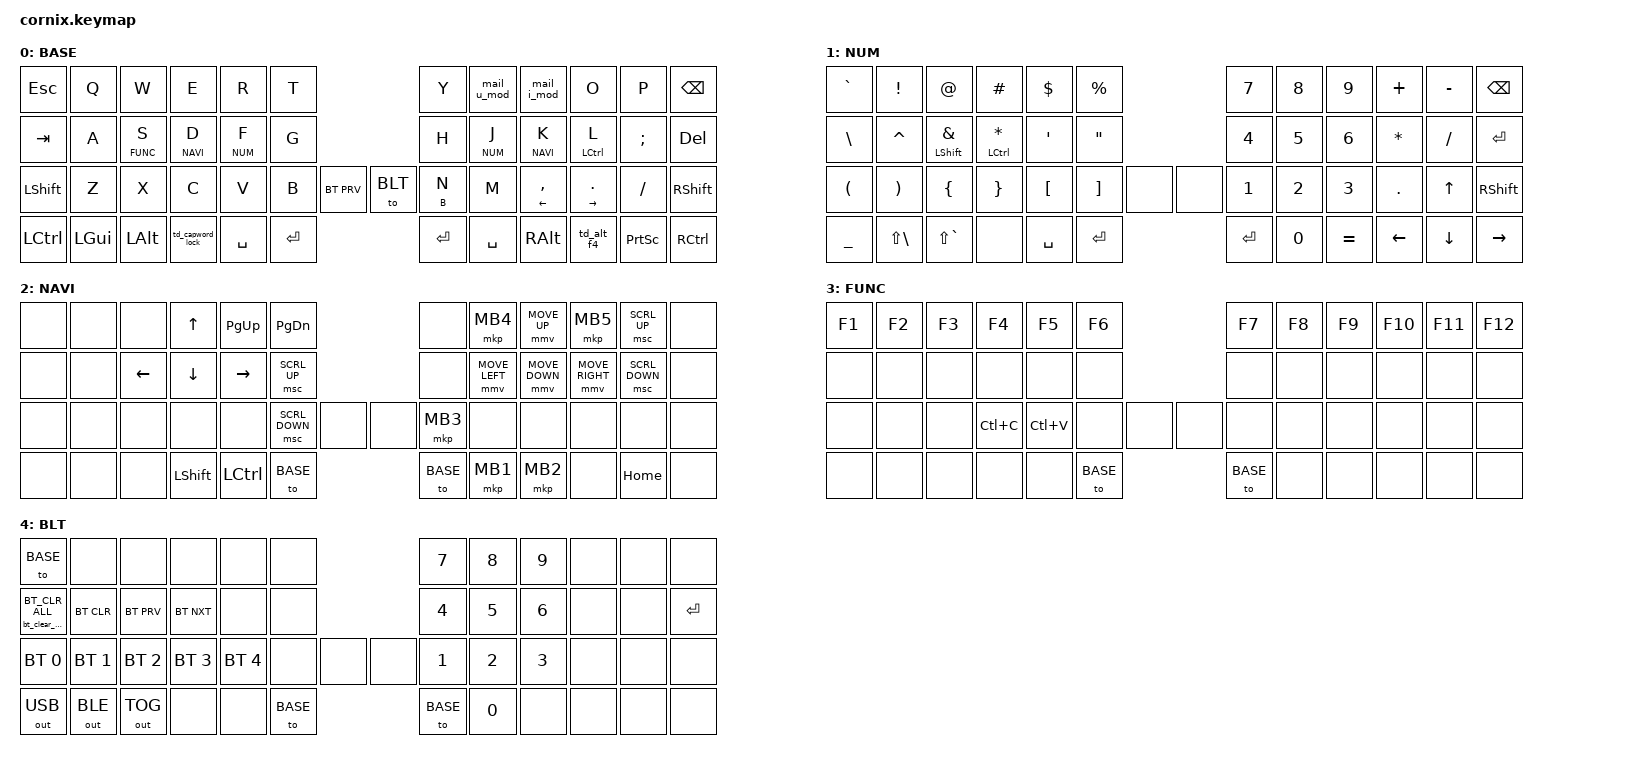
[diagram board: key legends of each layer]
/*
 * Copyright (c) 2020 The ZMK Contributors
 *
 * SPDX-License-Identifier: MIT
 */

#include "zmk-helpers/helper.h"
#include "includes/cornix54.h"

// Layer Mapping

#define BASE 0
#define NUM  1
#define NAVI 2
#define FUNC 3
#define BLT  4

// Group key positions in header files

#define KEYS_L LT0 LT1 LT2 LT3 LT4 LT5 LM0 LM1 LM2 LM3 LM4 LM5 LB0 LB1 LB2 LB3 LB4 LB5
#define KEYS_R RT0 RT1 RT2 RT3 RT4 RT5 RM0 RM1 RM2 RM3 RM4 RM5 RB0 RB1 RB2 RB3 RB4 RB5
#define KEYS_T LH1 LH0 RH0 RH1
#define ZMK_POINTING_DEFAULT_SCRL_VAL 15
#define ZMK_POINTING_DEFAULT_MOVE_VAL 1800

#include <behaviors.dtsi>
#include <dt-bindings/zmk/bt.h>
#include <dt-bindings/zmk/keys.h>
#include <dt-bindings/zmk/modifiers.h>
#include <dt-bindings/zmk/outputs.h>
#include <dt-bindings/zmk/pointing.h>

/ {
    behaviors {
        hm_l: homerow_mods_left {
            compatible = "zmk,behavior-hold-tap";
            #binding-cells = <2>;
            bindings = <&kp>, <&kp>;

            flavor = "balanced";
            tapping-term-ms = <250>;
            quick-tap-ms = <175>;                // repeat on tap-into-hold
            require-prior-idle-ms = <150>;
            hold-trigger-key-positions = <KEYS_R KEYS_T>;
            hold-trigger-on-release;
        };

        hm_r: homerow_mods_right {
            compatible = "zmk,behavior-hold-tap";
            #binding-cells = <2>;
            bindings = <&kp>, <&kp>;

            flavor = "balanced";
            tapping-term-ms = <200>;
            quick-tap-ms = <175>;
            require-prior-idle-ms = <150>;
            hold-trigger-key-positions = <KEYS_L KEYS_T>;
            hold-trigger-on-release;
        };

        // Guard against accidental deletion of all Bluetooth pairings.
        bt_clear_hold: bt_clear_hold {
            compatible = "zmk,behavior-hold-tap";
            #binding-cells = <2>;
            bindings = <&bt>, <&none>;
            flavor = "tap-preferred";
            tapping-term-ms = <3000>;
        };

        ht_b_n: hold_tap_b_n {
            compatible = "zmk,behavior-hold-tap";
            #binding-cells = <2>;
            flavor = "balanced";
            tapping-term-ms = <200>;
            quick-tap-ms = <175>;
            bindings = <&kp>, <&kp>;

            require-prior-idle-ms = <150>;
        };

        th: tap_key_hold_to {
            compatible = "zmk,behavior-hold-tap";
            #binding-cells = <2>;
            flavor = "tap-preferred"; // key first
            tapping-term-ms = <300>;  // <= 250ms press to layer
            bindings = <&to>, <&kp>;

            quick-tap-ms = <175>;
            require-prior-idle-ms = <150>;
        };

        lt: layer_tap {
            compatible = "zmk,behavior-hold-tap";
            #binding-cells = <2>;
            bindings = <&mo>, <&kp>;

            flavor = "tap-preferred";
            tapping-term-ms = <250>;
            quick-tap-ms = <200>;
            require-prior-idle-ms = <150>;
        };

        td_capword_lock: td_capword_lock {
            compatible = "zmk,behavior-tap-dance";
            label = "TD_CAPWORD_LOCK";
            #binding-cells = <0>;
            bindings = <&caps_word>, <&kp CAPS>;
        };

        td_mail_head: td_mail_head {
            compatible = "zmk,behavior-tap-dance";
            label = "TD_MAIL_HEAD";
            #binding-cells = <0>;
            bindings = <&kp U>, <&m_mail_head>;
            tapping-term-ms = <150>;
        };

        td_mail_tail: td_mail_tail {
            compatible = "zmk,behavior-tap-dance";
            label = "TD_MAIL_TAIL";
            #binding-cells = <0>;
            bindings = <&kp I>, <&m_mail_tail>;
            tapping-term-ms = <150>;
        };

        // Bypass tap-dance for U/I when a modifier is held.
        // Preserve the modifier so normal shortcuts and shifted letters work.
        mail_u_mod: mail_u_mod {
            compatible = "zmk,behavior-mod-morph";
            #binding-cells = <0>;
            bindings = <&td_mail_head>, <&kp U>;
            mods = <(MOD_LSFT | MOD_RSFT | MOD_LCTL | MOD_RCTL |
                     MOD_LALT | MOD_RALT | MOD_LGUI | MOD_RGUI)>;
            keep-mods = <(MOD_LSFT | MOD_RSFT | MOD_LCTL | MOD_RCTL |
                          MOD_LALT | MOD_RALT | MOD_LGUI | MOD_RGUI)>;
        };

        mail_i_mod: mail_i_mod {
            compatible = "zmk,behavior-mod-morph";
            #binding-cells = <0>;
            bindings = <&td_mail_tail>, <&kp I>;
            mods = <(MOD_LSFT | MOD_RSFT | MOD_LCTL | MOD_RCTL |
                     MOD_LALT | MOD_RALT | MOD_LGUI | MOD_RGUI)>;
            keep-mods = <(MOD_LSFT | MOD_RSFT | MOD_LCTL | MOD_RCTL |
                          MOD_LALT | MOD_RALT | MOD_LGUI | MOD_RGUI)>;
        };

        td_alt_f4: td_alt_f4 {
            compatible = "zmk,behavior-tap-dance";
            label = "TD_ALT_F4";
            #binding-cells = <0>;
            bindings = <&kp F5>, <&kp LA(F4)>;

            tapping-term-ms = <250>;
        };

        navi_scroll_enc: navi_scroll_enc {
            compatible = "zmk,behavior-sensor-rotate";
            #sensor-binding-cells = <0>;
            bindings = <&msc MOVE_Y(40)>, <&msc MOVE_Y(-40)>;
            tap-ms = <60>;
        };

        bt_prof_enc: bt_prof_enc {
            compatible = "zmk,behavior-sensor-rotate";
            #sensor-binding-cells = <0>;
            bindings = <&bt BT_NXT>, <&bt BT_PRV>;

            tap-ms = <30>;
        };

        hm_r_arrow: hm_r_arrow {
            compatible = "zmk,behavior-hold-tap";
            #binding-cells = <2>;
            bindings = <&kp>, <&kp>;

            flavor = "tap-preferred";
            tapping-term-ms = <300>;
            quick-tap-ms = <250>;
            require-prior-idle-ms = <200>;
            hold-trigger-key-positions = <KEYS_L KEYS_T>;
            hold-trigger-on-release;
            label = "HM_R_ARROW";
        };
    };

    macros {
        m_mail_head: m_mail_head {
            compatible = "zmk,behavior-macro";
            #binding-cells = <0>;
            wait-ms = <15>;
            tap-ms = <15>;
            // Korean IME initially active: 바디제어SE팀
            bindings
                = <&kp Q &kp K &kp E &kp L &kp W &kp P &kp D &kp J &kp RALT>
                , <&macro_wait_time 100>
                , <&kp LS(S)>
                , <&macro_wait_time 15>
                , <&kp LS(E) &kp RALT>
                , <&macro_wait_time 100>
                , <&kp X>
                , <&macro_wait_time 15>
                , <&kp L &kp A>;
            label = "M_MAIL_HEAD";
        };

        m_mail_tail: m_mail_tail {
            compatible = "zmk,behavior-macro";
            #binding-cells = <0>;
            wait-ms = <15>;
            tap-ms = <15>;
            bindings = <&kp R &kp K &kp A &kp T &kp K &kp G &kp K &kp Q &kp S &kp L &kp E &kp K &kp DOT>;
            label = "M_MAIL_TAIL";
        };
    };

    combos {
        compatible = "zmk,combos";

        ralt_combo {
            bindings = <&kp LG(L)>;
            key-positions = <48 47>;
            layers = <BASE>;
            timeout-ms = <50>;
            require-prior-idle-ms = <120>;
        };

        // Press both thumb Enter keys to toggle persistent NUM mode.
        combo_num_lock {
            bindings = <&tog NUM>;
            key-positions = <LH0 RH0>;
            layers = <BASE NUM>;
            timeout-ms = <50>;
        };
    };

    keymap {
        compatible = "zmk,keymap";

        default_layer {
            display-name = "BASE";
            bindings = <
&kp ESC     &kp Q     &kp W     &kp E             &kp R      &kp T                              &kp Y        &mail_u_mod  &mail_i_mod           &kp O                  &kp P        &kp BSPC
&kp TAB    &kp A     &th FUNC S   &lt NAVI D           &lt NUM F    &kp G                              &kp H        &lt NUM J        &lt NAVI K                 &hm_r LCTRL L          &kp SEMI     &kp DEL
&kp LSHFT  &kp Z     &kp X     &kp C             &kp V      &kp B      &bt BT_PRV  &to BLT      &ht_b_n B N  &kp M          &hm_r_arrow LEFT COMMA  &hm_r_arrow RIGHT DOT  &kp FSLH     &kp RSHFT
&kp LCTRL  &kp LGUI  &kp LALT  &td_capword_lock  &kp SPACE  &kp ENTER                          &kp ENTER    &kp SPACE      &kp RALT                &td_alt_f4             &kp PSCRN     &kp RCTRL
            >;

            sensor-bindings = <&inc_dec_kp C_VOL_UP C_VOL_DN>, <&bt_prof_enc>;
        };

        NUM_layer {
            display-name = "NUM";
            bindings = <
&kp GRAVE  &kp EXCL      &kp AT            &kp HASH           &kp DLLR   &kp PRCNT                &kp N7     &kp N8  &kp N9     &kp PLUS   &kp MINUS     &kp BSPC
&kp BSLH   &kp CARET     &hm_l LSHFT AMPS  &hm_l LCTRL ASTRK  &kp SQT    &kp DQT                  &kp N4     &kp N5  &kp N6     &kp ASTRK  &kp SLASH     &kp ENTER
&kp LPAR   &kp RPAR      &kp LBRC          &kp RBRC           &kp LBKT   &kp RBKT   &none  &none  &kp N1     &kp N2  &kp N3     &kp DOT    &kp UP        &kp RSHFT
&kp UNDER  &kp LS(BSLH)  &kp LS(GRAVE)     &none              &kp SPACE  &kp ENTER                &kp ENTER  &kp N0  &kp EQUAL  &kp LEFT   &kp DOWN       &kp RIGHT
            >;

            sensor-bindings =
                <&inc_dec_kp C_VOL_UP C_VOL_DN>,
                <&inc_dec_kp UP DOWN>;
        };

        Navi_layer {
            display-name = "NAVI";
            bindings = <
&none  &none  &none     &kp UP     &kp PAGE_UP  &kp PAGE_DOWN                 &none  &mkp MB4        &mmv MOVE_UP    &mkp MB5         &msc SCRL_UP    &none
&none  &none  &kp LEFT  &kp DOWN   &kp RIGHT    &msc SCRL_UP                  &none  &mmv MOVE_LEFT  &mmv MOVE_DOWN  &mmv MOVE_RIGHT  &msc SCRL_DOWN  &none
&none  &none  &none     &none      &none        &msc SCRL_DOWN  &none  &none  &mkp MB3  &none           &none           &none            &none           &none
&none  &none  &none     &kp LSHFT  &kp LCTRL    &to BASE                         &to BASE  &mkp MB1        &mkp MB2        &none            &kp HOME        &none
            >;

            sensor-bindings =
                <&inc_dec_kp C_VOL_UP C_VOL_DN>,
                <&navi_scroll_enc>;
        };

        Function_layer {
            display-name = "FUNC";
            bindings = <
&kp F1  &kp F2  &kp F3  &kp F4     &kp F5     &kp F6                &kp F7  &kp F8  &kp F9  &kp F10  &kp F11  &kp F12
&none   &none   &none   &none      &none      &none                 &none   &none   &none   &none    &none    &none
&none   &none   &none   &kp LC(C)  &kp LC(V)  &none   &none  &none  &none   &none   &none   &none    &none    &none
&none   &none   &none   &none      &none      &to BASE                 &to BASE   &none   &none   &none    &none    &none
            >;

            sensor-bindings =
                <&inc_dec_kp C_VOL_UP C_VOL_DN>,
                <&inc_dec_kp UP DOWN>;
        };

        BLT_layer {
            display-name = "BLT";
            bindings = <
&to BASE           &none         &none         &none         &none         &none                &kp N7  &kp N8        &kp N9  &none  &none    &none
&bt_clear_hold BT_CLR_ALL  &bt BT_CLR    &bt BT_PRV    &bt BT_NXT    &none         &none                &kp N4  &kp N5        &kp N6  &none  &none    &kp ENTER
&bt BT_SEL 0    &bt BT_SEL 1  &bt BT_SEL 2  &bt BT_SEL 3  &bt BT_SEL 4  &none  &none  &none  &kp N1  &kp N2        &kp N3  &none  &none    &none
&out OUT_USB    &out OUT_BLE  &out OUT_TOG  &none         &none         &to BASE                &to BASE   &kp NUMBER_0  &none   &none  &none    &none
            >;

            sensor-bindings = <&inc_dec_kp C_VOL_UP C_VOL_DN>, <&bt_prof_enc>;
        };
    };
};

// NAVI pointer acceleration and travel speed.
// The existing &mmv MOVE_* key bindings use the value above.
&mmv {
    time-to-max-speed-ms = <250>;
    acceleration-exponent = <1>;
};
